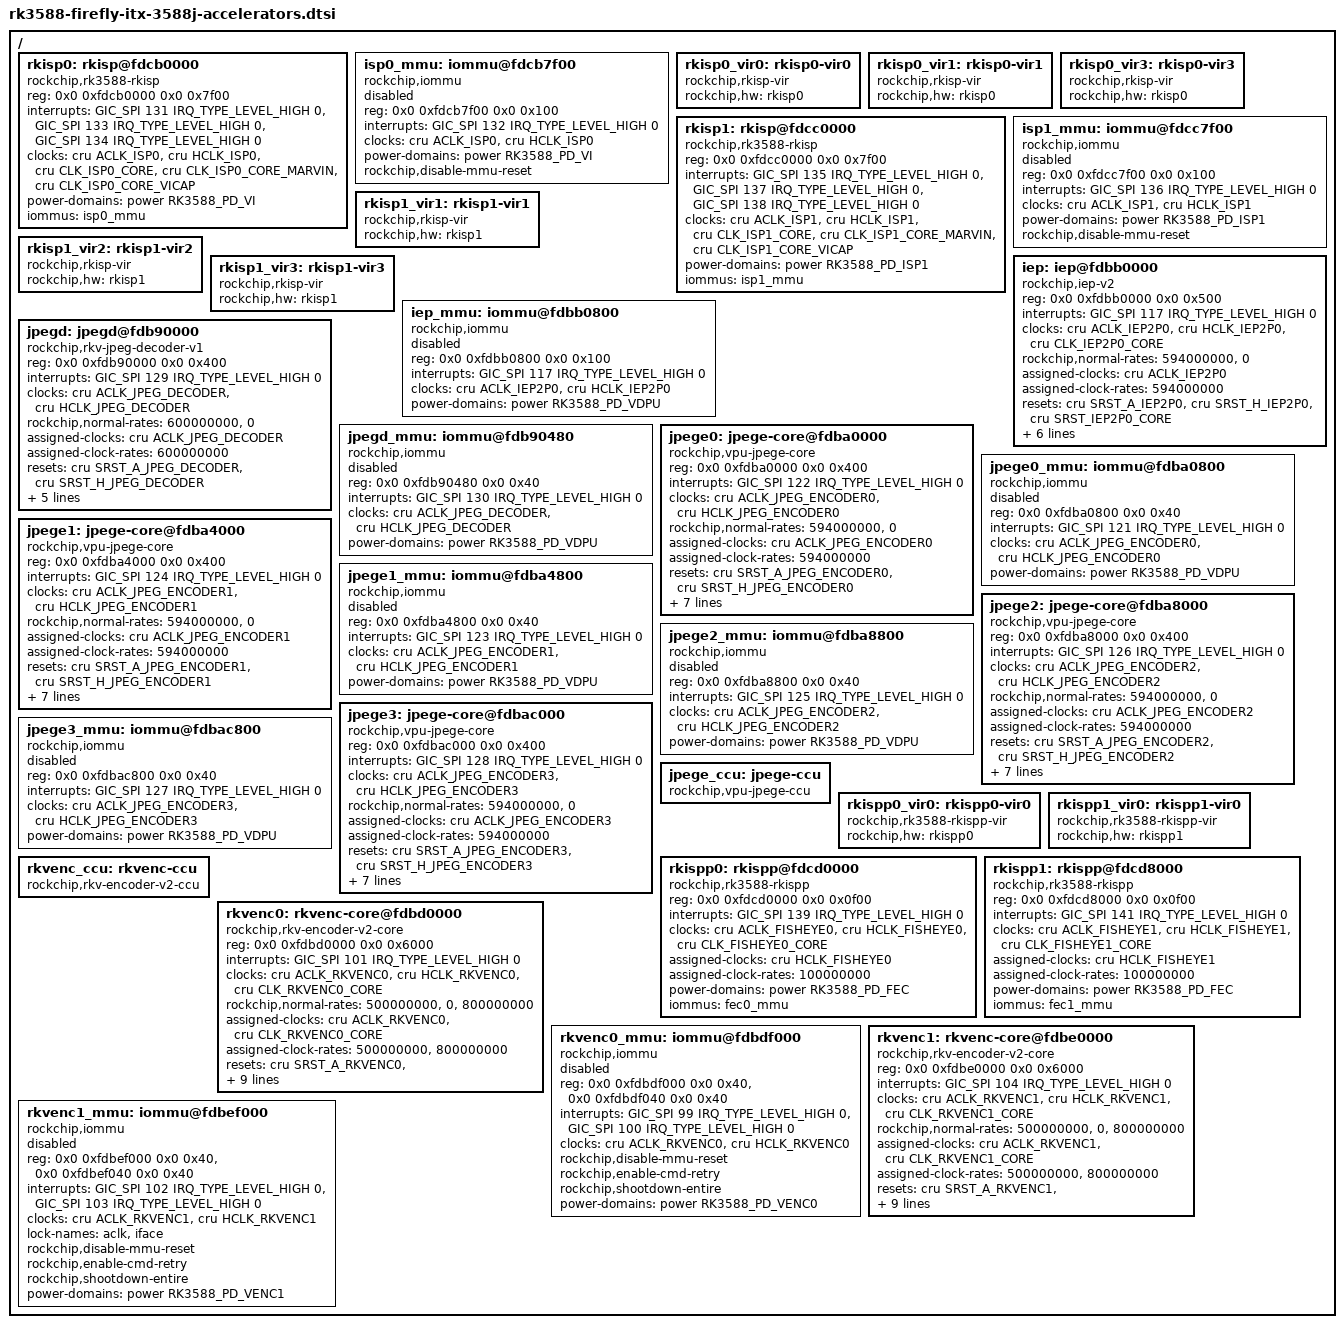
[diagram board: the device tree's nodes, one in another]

/ {
	rkisp0: rkisp@fdcb0000 {
		compatible = "rockchip,rk3588-rkisp";
		reg = <0x0 0xfdcb0000 0x0 0x7f00>;
		interrupts = <GIC_SPI 131 IRQ_TYPE_LEVEL_HIGH 0>,
					 <GIC_SPI 133 IRQ_TYPE_LEVEL_HIGH 0>,
					 <GIC_SPI 134 IRQ_TYPE_LEVEL_HIGH 0>;
		interrupt-names = "isp_irq", "mi_irq", "mipi_irq";
		clocks = <&cru ACLK_ISP0>, <&cru HCLK_ISP0>,
				 <&cru CLK_ISP0_CORE>, <&cru CLK_ISP0_CORE_MARVIN>,
				 <&cru CLK_ISP0_CORE_VICAP>;
		clock-names = "aclk_isp", "hclk_isp", "clk_isp_core",
					  "clk_isp_core_marvin", "clk_isp_core_vicap";
		power-domains = <&power RK3588_PD_VI>;
		iommus = <&isp0_mmu>;
		status = "okay";
	};

	isp0_mmu: iommu@fdcb7f00 {
		compatible = "rockchip,iommu";
		reg = <0x0 0xfdcb7f00 0x0 0x100>;
		interrupts = <GIC_SPI 132 IRQ_TYPE_LEVEL_HIGH 0>;
		interrupt-names = "isp0_mmu";
		clocks = <&cru ACLK_ISP0>, <&cru HCLK_ISP0>;
		clock-names = "aclk", "iface";
		power-domains = <&power RK3588_PD_VI>;
		#iommu-cells = <0>;
		rockchip,disable-mmu-reset;
		status = "disabled";
	};

	rkisp0_vir0: rkisp0-vir0 {
		compatible = "rockchip,rkisp-vir";
		rockchip,hw = <&rkisp0>;
		/*
		 * dual isp process image case
		 * other rkisp hw and virtual nodes should disabled
		 * rockchip,hw = <&rkisp_unite>;
		 */
		status = "okay";
	};

	rkisp0_vir1: rkisp0-vir1 {
		compatible = "rockchip,rkisp-vir";
		rockchip,hw = <&rkisp0>;
		status = "okay";
	};

	rkisp0_vir3: rkisp0-vir3 {
		compatible = "rockchip,rkisp-vir";
		rockchip,hw = <&rkisp0>;
		status = "okay";
	};

	rkisp1: rkisp@fdcc0000 {
		compatible = "rockchip,rk3588-rkisp";
		reg = <0x0 0xfdcc0000 0x0 0x7f00>;
		interrupts = <GIC_SPI 135 IRQ_TYPE_LEVEL_HIGH 0>,
					 <GIC_SPI 137 IRQ_TYPE_LEVEL_HIGH 0>,
					 <GIC_SPI 138 IRQ_TYPE_LEVEL_HIGH 0>;
		interrupt-names = "isp_irq", "mi_irq", "mipi_irq";
		clocks = <&cru ACLK_ISP1>, <&cru HCLK_ISP1>,
				 <&cru CLK_ISP1_CORE>, <&cru CLK_ISP1_CORE_MARVIN>,
				 <&cru CLK_ISP1_CORE_VICAP>;
		clock-names = "aclk_isp", "hclk_isp", "clk_isp_core",
					  "clk_isp_core_marvin", "clk_isp_core_vicap";
		power-domains = <&power RK3588_PD_ISP1>;
		iommus = <&isp1_mmu>;
		status = "okay";
	};

	isp1_mmu: iommu@fdcc7f00 {
		compatible = "rockchip,iommu";
		reg = <0x0 0xfdcc7f00 0x0 0x100>;
		interrupts = <GIC_SPI 136 IRQ_TYPE_LEVEL_HIGH 0>;
		interrupt-names = "isp1_mmu";
		clocks = <&cru ACLK_ISP1>, <&cru HCLK_ISP1>;
		clock-names = "aclk", "iface";
		power-domains = <&power RK3588_PD_ISP1>;
		#iommu-cells = <0>;
		rockchip,disable-mmu-reset;
		status = "disabled";
	};

	rkisp1_vir1: rkisp1-vir1 {
		compatible = "rockchip,rkisp-vir";
		rockchip,hw = <&rkisp1>;
		status = "okay";
	};

	rkisp1_vir2: rkisp1-vir2 {
		compatible = "rockchip,rkisp-vir";
		rockchip,hw = <&rkisp1>;
		status = "okay";
	};

	rkisp1_vir3: rkisp1-vir3 {
		compatible = "rockchip,rkisp-vir";
		rockchip,hw = <&rkisp1>;
		status = "okay";
	};

	iep: iep@fdbb0000 {
		compatible = "rockchip,iep-v2";
		reg = <0x0 0xfdbb0000 0x0 0x500>;
		interrupts = <GIC_SPI 117 IRQ_TYPE_LEVEL_HIGH 0>;
		interrupt-names = "irq_iep";
		clocks = <&cru ACLK_IEP2P0>, <&cru HCLK_IEP2P0>, <&cru CLK_IEP2P0_CORE>;
		clock-names = "aclk", "hclk", "sclk";
		rockchip,normal-rates = <594000000>, <0>;
		assigned-clocks = <&cru ACLK_IEP2P0>;
		assigned-clock-rates = <594000000>;
		resets = <&cru SRST_A_IEP2P0>, <&cru SRST_H_IEP2P0>, <&cru SRST_IEP2P0_CORE>;
		reset-names = "rst_a", "rst_h", "rst_s";
		rockchip,skip-pmu-idle-request;
		rockchip,disable-auto-freq;
		power-domains = <&power RK3588_PD_VDPU>;
		rockchip,srv = <&mpp_srv>;
		rockchip,taskqueue-node = <6>;
		iommus = <&iep_mmu>;
		status = "okay";
	};

	iep_mmu: iommu@fdbb0800 {
		compatible = "rockchip,iommu";
		reg = <0x0 0xfdbb0800 0x0 0x100>;
		interrupts = <GIC_SPI 117 IRQ_TYPE_LEVEL_HIGH 0>;
		interrupt-names = "irq_iep_mmu";
		clocks = <&cru ACLK_IEP2P0>, <&cru HCLK_IEP2P0>;
		clock-names = "aclk", "iface";
		#iommu-cells = <0>;
		power-domains = <&power RK3588_PD_VDPU>;
		status = "disabled";
	};

	jpegd: jpegd@fdb90000 {
		compatible = "rockchip,rkv-jpeg-decoder-v1";
		reg = <0x0 0xfdb90000 0x0 0x400>;
		interrupts = <GIC_SPI 129 IRQ_TYPE_LEVEL_HIGH 0>;
		interrupt-names = "irq_jpegd";
		clocks = <&cru ACLK_JPEG_DECODER>, <&cru HCLK_JPEG_DECODER>;
		clock-names = "aclk_vcodec", "hclk_vcodec";
		rockchip,normal-rates = <600000000>, <0>;
		assigned-clocks = <&cru ACLK_JPEG_DECODER>;
		assigned-clock-rates = <600000000>;
		resets = <&cru SRST_A_JPEG_DECODER>, <&cru SRST_H_JPEG_DECODER>;
		reset-names = "video_a", "video_h";
		rockchip,skip-pmu-idle-request;
		iommus = <&jpegd_mmu>;
		rockchip,srv = <&mpp_srv>;
		rockchip,taskqueue-node = <1>;
		power-domains = <&power RK3588_PD_VDPU>;
		status = "okay";
	};

	jpegd_mmu: iommu@fdb90480 {
		compatible = "rockchip,iommu";
		reg = <0x0 0xfdb90480 0x0 0x40>;
		interrupts = <GIC_SPI 130 IRQ_TYPE_LEVEL_HIGH 0>;
		interrupt-names = "irq_jpegd_mmu";
		clocks = <&cru ACLK_JPEG_DECODER>, <&cru HCLK_JPEG_DECODER>;
		clock-names = "aclk", "iface";
		power-domains = <&power RK3588_PD_VDPU>;
		#iommu-cells = <0>;
		status = "disabled";
	};

	jpege0: jpege-core@fdba0000 {
		compatible = "rockchip,vpu-jpege-core";
		reg = <0x0 0xfdba0000 0x0 0x400>;
		interrupts = <GIC_SPI 122 IRQ_TYPE_LEVEL_HIGH 0>;
		interrupt-names = "irq_jpege0";
		clocks = <&cru ACLK_JPEG_ENCODER0>, <&cru HCLK_JPEG_ENCODER0>;
		clock-names = "aclk_vcodec", "hclk_vcodec";
		rockchip,normal-rates = <594000000>, <0>;
		assigned-clocks = <&cru ACLK_JPEG_ENCODER0>;
		assigned-clock-rates = <594000000>;
		resets = <&cru SRST_A_JPEG_ENCODER0>, <&cru SRST_H_JPEG_ENCODER0>;
		reset-names = "video_a", "video_h";
		rockchip,skip-pmu-idle-request;
		rockchip,disable-auto-freq;
		iommus = <&jpege0_mmu>;
		rockchip,srv = <&mpp_srv>;
		rockchip,taskqueue-node = <2>;
		rockchip,ccu = <&jpege_ccu>;
		power-domains = <&power RK3588_PD_VDPU>;
		status = "okay";
	};

	jpege0_mmu: iommu@fdba0800 {
		compatible = "rockchip,iommu";
		reg = <0x0 0xfdba0800 0x0 0x40>;
		interrupts = <GIC_SPI 121 IRQ_TYPE_LEVEL_HIGH 0>;
		interrupt-names = "irq_jpege0_mmu";
		clocks = <&cru ACLK_JPEG_ENCODER0>, <&cru HCLK_JPEG_ENCODER0>;
		clock-names = "aclk", "iface";
		power-domains = <&power RK3588_PD_VDPU>;
		#iommu-cells = <0>;
		status = "disabled";
	};

	jpege1: jpege-core@fdba4000 {
		compatible = "rockchip,vpu-jpege-core";
		reg = <0x0 0xfdba4000 0x0 0x400>;
		interrupts = <GIC_SPI 124 IRQ_TYPE_LEVEL_HIGH 0>;
		interrupt-names = "irq_jpege1";
		clocks = <&cru ACLK_JPEG_ENCODER1>, <&cru HCLK_JPEG_ENCODER1>;
		clock-names = "aclk_vcodec", "hclk_vcodec";
		rockchip,normal-rates = <594000000>, <0>;
		assigned-clocks = <&cru ACLK_JPEG_ENCODER1>;
		assigned-clock-rates = <594000000>;
		resets = <&cru SRST_A_JPEG_ENCODER1>, <&cru SRST_H_JPEG_ENCODER1>;
		reset-names = "video_a", "video_h";
		rockchip,skip-pmu-idle-request;
		rockchip,disable-auto-freq;
		iommus = <&jpege1_mmu>;
		rockchip,srv = <&mpp_srv>;
		rockchip,taskqueue-node = <2>;
		rockchip,ccu = <&jpege_ccu>;
		power-domains = <&power RK3588_PD_VDPU>;
		status = "okay";
	};

	jpege1_mmu: iommu@fdba4800 {
		compatible = "rockchip,iommu";
		reg = <0x0 0xfdba4800 0x0 0x40>;
		interrupts = <GIC_SPI 123 IRQ_TYPE_LEVEL_HIGH 0>;
		interrupt-names = "irq_jpege1_mmu";
		clocks = <&cru ACLK_JPEG_ENCODER1>, <&cru HCLK_JPEG_ENCODER1>;
		clock-names = "aclk", "iface";
		power-domains = <&power RK3588_PD_VDPU>;
		#iommu-cells = <0>;
		status = "disabled";
	};

	jpege2: jpege-core@fdba8000 {
		compatible = "rockchip,vpu-jpege-core";
		reg = <0x0 0xfdba8000 0x0 0x400>;
		interrupts = <GIC_SPI 126 IRQ_TYPE_LEVEL_HIGH 0>;
		interrupt-names = "irq_jpege2";
		clocks = <&cru ACLK_JPEG_ENCODER2>, <&cru HCLK_JPEG_ENCODER2>;
		clock-names = "aclk_vcodec", "hclk_vcodec";
		rockchip,normal-rates = <594000000>, <0>;
		assigned-clocks = <&cru ACLK_JPEG_ENCODER2>;
		assigned-clock-rates = <594000000>;
		resets = <&cru SRST_A_JPEG_ENCODER2>, <&cru SRST_H_JPEG_ENCODER2>;
		reset-names = "video_a", "video_h";
		rockchip,skip-pmu-idle-request;
		rockchip,disable-auto-freq;
		iommus = <&jpege2_mmu>;
		rockchip,srv = <&mpp_srv>;
		rockchip,taskqueue-node = <2>;
		rockchip,ccu = <&jpege_ccu>;
		power-domains = <&power RK3588_PD_VDPU>;
		status = "okay";
	};

	jpege2_mmu: iommu@fdba8800 {
		compatible = "rockchip,iommu";
		reg = <0x0 0xfdba8800 0x0 0x40>;
		interrupts = <GIC_SPI 125 IRQ_TYPE_LEVEL_HIGH 0>;
		interrupt-names = "irq_jpege2_mmu";
		clocks = <&cru ACLK_JPEG_ENCODER2>, <&cru HCLK_JPEG_ENCODER2>;
		clock-names = "aclk", "iface";
		power-domains = <&power RK3588_PD_VDPU>;
		#iommu-cells = <0>;
		status = "disabled";
	};

	jpege3: jpege-core@fdbac000 {
		compatible = "rockchip,vpu-jpege-core";
		reg = <0x0 0xfdbac000 0x0 0x400>;
		interrupts = <GIC_SPI 128 IRQ_TYPE_LEVEL_HIGH 0>;
		interrupt-names = "irq_jpege3";
		clocks = <&cru ACLK_JPEG_ENCODER3>, <&cru HCLK_JPEG_ENCODER3>;
		clock-names = "aclk_vcodec", "hclk_vcodec";
		rockchip,normal-rates = <594000000>, <0>;
		assigned-clocks = <&cru ACLK_JPEG_ENCODER3>;
		assigned-clock-rates = <594000000>;
		resets = <&cru SRST_A_JPEG_ENCODER3>, <&cru SRST_H_JPEG_ENCODER3>;
		reset-names = "video_a", "video_h";
		rockchip,skip-pmu-idle-request;
		rockchip,disable-auto-freq;
		iommus = <&jpege3_mmu>;
		rockchip,srv = <&mpp_srv>;
		rockchip,taskqueue-node = <2>;
		rockchip,ccu = <&jpege_ccu>;
		power-domains = <&power RK3588_PD_VDPU>;
		status = "okay";
	};

	jpege3_mmu: iommu@fdbac800 {
		compatible = "rockchip,iommu";
		reg = <0x0 0xfdbac800 0x0 0x40>;
		interrupts = <GIC_SPI 127 IRQ_TYPE_LEVEL_HIGH 0>;
		interrupt-names = "irq_jpege3_mmu";
		clocks = <&cru ACLK_JPEG_ENCODER3>, <&cru HCLK_JPEG_ENCODER3>;
		clock-names = "aclk", "iface";
		power-domains = <&power RK3588_PD_VDPU>;
		#iommu-cells = <0>;
		status = "disabled";
	};

	jpege_ccu: jpege-ccu {
		compatible = "rockchip,vpu-jpege-ccu";
		status = "okay";
	};

	rkispp0_vir0: rkispp0-vir0 {
		compatible = "rockchip,rk3588-rkispp-vir";
		rockchip,hw = <&rkispp0>;
		status = "okay";
	};

	rkispp1_vir0: rkispp1-vir0 {
		compatible = "rockchip,rk3588-rkispp-vir";
		rockchip,hw = <&rkispp1>;
		status = "okay";
	};

	rkispp0: rkispp@fdcd0000 {
		compatible = "rockchip,rk3588-rkispp";
		reg = <0x0 0xfdcd0000 0x0 0x0f00>;
		interrupts = <GIC_SPI 139 IRQ_TYPE_LEVEL_HIGH 0>;
		interrupt-names = "fec_irq";
		clocks = <&cru ACLK_FISHEYE0>, <&cru HCLK_FISHEYE0>,
				 <&cru CLK_FISHEYE0_CORE>;
		clock-names = "aclk_ispp", "hclk_ispp", "clk_ispp";
		assigned-clocks = <&cru HCLK_FISHEYE0>;
		assigned-clock-rates = <100000000>;
		power-domains = <&power RK3588_PD_FEC>;
		iommus = <&fec0_mmu>;
		status = "okay";
	};

	rkispp1: rkispp@fdcd8000 {
		compatible = "rockchip,rk3588-rkispp";
		reg = <0x0 0xfdcd8000 0x0 0x0f00>;
		interrupts = <GIC_SPI 141 IRQ_TYPE_LEVEL_HIGH 0>;
		interrupt-names = "fec_irq";
		clocks = <&cru ACLK_FISHEYE1>, <&cru HCLK_FISHEYE1>,
				 <&cru CLK_FISHEYE1_CORE>;
		clock-names = "aclk_ispp", "hclk_ispp", "clk_ispp";
		assigned-clocks = <&cru HCLK_FISHEYE1>;
		assigned-clock-rates = <100000000>;
		power-domains = <&power RK3588_PD_FEC>;
		iommus = <&fec1_mmu>;
		status = "okay";
	};

	rkvenc_ccu: rkvenc-ccu {
		compatible = "rockchip,rkv-encoder-v2-ccu";
		status = "okay";
	};

	rkvenc0: rkvenc-core@fdbd0000 {
		compatible = "rockchip,rkv-encoder-v2-core";
		reg = <0x0 0xfdbd0000 0x0 0x6000>;
		interrupts = <GIC_SPI 101 IRQ_TYPE_LEVEL_HIGH 0>;
		interrupt-names = "irq_rkvenc0";
		clocks = <&cru ACLK_RKVENC0>, <&cru HCLK_RKVENC0>, <&cru CLK_RKVENC0_CORE>;
		clock-names = "aclk_vcodec", "hclk_vcodec", "clk_core";
		rockchip,normal-rates = <500000000>, <0>, <800000000>;
		assigned-clocks = <&cru ACLK_RKVENC0>, <&cru CLK_RKVENC0_CORE>;
		assigned-clock-rates = <500000000>, <800000000>;
		resets = <&cru SRST_A_RKVENC0>, <&cru SRST_H_RKVENC0>, <&cru SRST_RKVENC0_CORE>;
		reset-names = "video_a", "video_h", "video_core";
		rockchip,skip-pmu-idle-request;
		iommus = <&rkvenc0_mmu>;
		rockchip,srv = <&mpp_srv>;
		rockchip,ccu = <&rkvenc_ccu>;
		rockchip,taskqueue-node = <7>;
		rockchip,task-capacity = <8>;
		power-domains = <&power RK3588_PD_VENC0>;
		operating-points-v2 = <&venc_opp_table>;
		status = "okay";
	};

	rkvenc0_mmu: iommu@fdbdf000 {
		compatible = "rockchip,iommu";
		reg = <0x0 0xfdbdf000 0x0 0x40>, <0x0 0xfdbdf040 0x0 0x40>;
		interrupts = <GIC_SPI 99 IRQ_TYPE_LEVEL_HIGH 0>,
					 <GIC_SPI 100 IRQ_TYPE_LEVEL_HIGH 0>;
		interrupt-names = "irq_rkvenc0_mmu0", "irq_rkvenc0_mmu1";
		clocks = <&cru ACLK_RKVENC0>, <&cru HCLK_RKVENC0>;
		clock-names = "aclk", "iface";
		rockchip,disable-mmu-reset;
		rockchip,enable-cmd-retry;
		rockchip,shootdown-entire;
		#iommu-cells = <0>;
		power-domains = <&power RK3588_PD_VENC0>;
		status = "disabled";
	};

	rkvenc1: rkvenc-core@fdbe0000 {
		compatible = "rockchip,rkv-encoder-v2-core";
		reg = <0x0 0xfdbe0000 0x0 0x6000>;
		interrupts = <GIC_SPI 104 IRQ_TYPE_LEVEL_HIGH 0>;
		interrupt-names = "irq_rkvenc1";
		clocks = <&cru ACLK_RKVENC1>, <&cru HCLK_RKVENC1>, <&cru CLK_RKVENC1_CORE>;
		clock-names = "aclk_vcodec", "hclk_vcodec", "clk_core";
		rockchip,normal-rates = <500000000>, <0>, <800000000>;
		assigned-clocks = <&cru ACLK_RKVENC1>, <&cru CLK_RKVENC1_CORE>;
		assigned-clock-rates = <500000000>, <800000000>;
		resets = <&cru SRST_A_RKVENC1>, <&cru SRST_H_RKVENC1>, <&cru SRST_RKVENC1_CORE>;
		reset-names = "video_a", "video_h", "video_core";
		rockchip,skip-pmu-idle-request;
		iommus = <&rkvenc1_mmu>;
		rockchip,srv = <&mpp_srv>;
		rockchip,ccu = <&rkvenc_ccu>;
		rockchip,taskqueue-node = <7>;
		rockchip,task-capacity = <8>;
		power-domains = <&power RK3588_PD_VENC1>;
		operating-points-v2 = <&venc_opp_table>;
		status = "okay";
	};

	rkvenc1_mmu: iommu@fdbef000 {
		compatible = "rockchip,iommu";
		reg = <0x0 0xfdbef000 0x0 0x40>, <0x0 0xfdbef040 0x0 0x40>;
		interrupts = <GIC_SPI 102 IRQ_TYPE_LEVEL_HIGH 0>,
					 <GIC_SPI 103 IRQ_TYPE_LEVEL_HIGH 0>;
		interrupt-names = "irq_rkvenc1_mmu0", "irq_rkvenc1_mmu1";
		clocks = <&cru ACLK_RKVENC1>, <&cru HCLK_RKVENC1>;
		lock-names = "aclk", "iface";
		rockchip,disable-mmu-reset;
		rockchip,enable-cmd-retry;
		rockchip,shootdown-entire;
		#iommu-cells = <0>;
		power-domains = <&power RK3588_PD_VENC1>;
		status = "disabled";
	};

};
